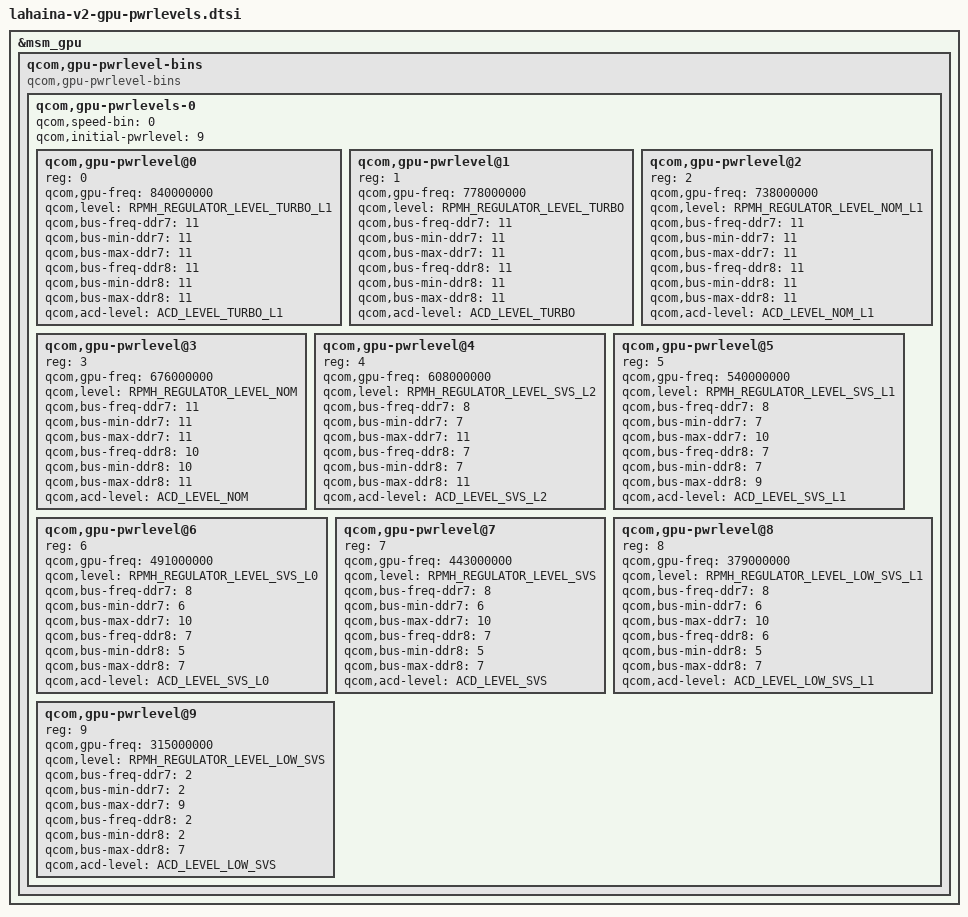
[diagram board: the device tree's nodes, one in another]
// SPDX-License-Identifier: BSD-3-Clause
/*
 * Copyright (c) Qualcomm Technologies, Inc. and/or its subsidiaries.
 */

/* ACD Control register values */
#define ACD_LEVEL_TURBO_L1     0x882a5ffd
#define ACD_LEVEL_TURBO        0xa82a5ffd
#define ACD_LEVEL_NOM_L1       0xa82a5ffd
#define ACD_LEVEL_NOM          0x882b5ffd
#define ACD_LEVEL_SVS_L2       0xa82b5ffd
#define ACD_LEVEL_SVS_L1       0xa82c5ffd
#define ACD_LEVEL_SVS_L0       0xa82c5ffd
#define ACD_LEVEL_SVS          0xa82d5ffd
#define ACD_LEVEL_LOW_SVS_L1   0x882e5ffd
#define ACD_LEVEL_LOW_SVS      0x882f5ffd

&msm_gpu {
	qcom,gpu-pwrlevel-bins {
		#address-cells = <1>;
		#size-cells = <0>;

		compatible = "qcom,gpu-pwrlevel-bins";

		qcom,gpu-pwrlevels-0 {
			#address-cells = <1>;
			#size-cells = <0>;

			qcom,speed-bin = <0>;
			qcom,initial-pwrlevel = <9>;

			/* TURBO_L1 */
			qcom,gpu-pwrlevel@0 {
				reg = <0>;
				qcom,gpu-freq = <840000000>;
				qcom,level = <RPMH_REGULATOR_LEVEL_TURBO_L1>;

				qcom,bus-freq-ddr7 = <11>;
				qcom,bus-min-ddr7 = <11>;
				qcom,bus-max-ddr7 = <11>;

				qcom,bus-freq-ddr8 = <11>;
				qcom,bus-min-ddr8 = <11>;
				qcom,bus-max-ddr8 = <11>;

				qcom,acd-level = <ACD_LEVEL_TURBO_L1>;
			};

			/* TURBO */
			qcom,gpu-pwrlevel@1 {
				reg = <1>;
				qcom,gpu-freq = <778000000>;
				qcom,level = <RPMH_REGULATOR_LEVEL_TURBO>;

				qcom,bus-freq-ddr7 = <11>;
				qcom,bus-min-ddr7 = <11>;
				qcom,bus-max-ddr7 = <11>;

				qcom,bus-freq-ddr8 = <11>;
				qcom,bus-min-ddr8 = <11>;
				qcom,bus-max-ddr8 = <11>;

				qcom,acd-level = <ACD_LEVEL_TURBO>;
			};

			/* NOM_L1 */
			qcom,gpu-pwrlevel@2 {
				reg = <2>;
				qcom,gpu-freq = <738000000>;
				qcom,level = <RPMH_REGULATOR_LEVEL_NOM_L1>;

				qcom,bus-freq-ddr7 = <11>;
				qcom,bus-min-ddr7 = <11>;
				qcom,bus-max-ddr7 = <11>;

				qcom,bus-freq-ddr8 = <11>;
				qcom,bus-min-ddr8 = <11>;
				qcom,bus-max-ddr8 = <11>;

				qcom,acd-level = <ACD_LEVEL_NOM_L1>;
			};

			/* NOM */
			qcom,gpu-pwrlevel@3 {
				reg = <3>;
				qcom,gpu-freq = <676000000>;
				qcom,level = <RPMH_REGULATOR_LEVEL_NOM>;

				qcom,bus-freq-ddr7 = <11>;
				qcom,bus-min-ddr7 = <11>;
				qcom,bus-max-ddr7 = <11>;

				qcom,bus-freq-ddr8 = <10>;
				qcom,bus-min-ddr8 = <10>;
				qcom,bus-max-ddr8 = <11>;

				qcom,acd-level = <ACD_LEVEL_NOM>;
			};

			/* SVS_L2 */
			qcom,gpu-pwrlevel@4 {
				reg = <4>;
				qcom,gpu-freq = <608000000>;
				qcom,level = <RPMH_REGULATOR_LEVEL_SVS_L2>;

				qcom,bus-freq-ddr7 = <8>;
				qcom,bus-min-ddr7 = <7>;
				qcom,bus-max-ddr7 = <11>;

				qcom,bus-freq-ddr8 = <7>;
				qcom,bus-min-ddr8 = <7>;
				qcom,bus-max-ddr8 = <11>;

				qcom,acd-level = <ACD_LEVEL_SVS_L2>;
			};

			/* SVS_L1 */
			qcom,gpu-pwrlevel@5 {
				reg = <5>;
				qcom,gpu-freq = <540000000>;
				qcom,level = <RPMH_REGULATOR_LEVEL_SVS_L1>;

				qcom,bus-freq-ddr7 = <8>;
				qcom,bus-min-ddr7 = <7>;
				qcom,bus-max-ddr7 = <10>;

				qcom,bus-freq-ddr8 = <7>;
				qcom,bus-min-ddr8 = <7>;
				qcom,bus-max-ddr8 = <9>;

				qcom,acd-level = <ACD_LEVEL_SVS_L1>;
			};

			/* SVS_L0 */
			qcom,gpu-pwrlevel@6 {
				reg = <6>;
				qcom,gpu-freq = <491000000>;
				qcom,level = <RPMH_REGULATOR_LEVEL_SVS_L0>;

				qcom,bus-freq-ddr7 = <8>;
				qcom,bus-min-ddr7 = <6>;
				qcom,bus-max-ddr7 = <10>;

				qcom,bus-freq-ddr8 = <7>;
				qcom,bus-min-ddr8 = <5>;
				qcom,bus-max-ddr8 = <7>;

				qcom,acd-level = <ACD_LEVEL_SVS_L0>;
			};

			/* SVS */
			qcom,gpu-pwrlevel@7 {
				reg = <7>;
				qcom,gpu-freq = <443000000>;
				qcom,level = <RPMH_REGULATOR_LEVEL_SVS>;

				qcom,bus-freq-ddr7 = <8>;
				qcom,bus-min-ddr7 = <6>;
				qcom,bus-max-ddr7 = <10>;

				qcom,bus-freq-ddr8 = <7>;
				qcom,bus-min-ddr8 = <5>;
				qcom,bus-max-ddr8 = <7>;

				qcom,acd-level = <ACD_LEVEL_SVS>;
			};

			/* LOW_SVS_L1 */
			qcom,gpu-pwrlevel@8 {
				reg = <8>;
				qcom,gpu-freq = <379000000>;
				qcom,level = <RPMH_REGULATOR_LEVEL_LOW_SVS_L1>;

				qcom,bus-freq-ddr7 = <8>;
				qcom,bus-min-ddr7 = <6>;
				qcom,bus-max-ddr7 = <10>;

				qcom,bus-freq-ddr8 = <6>;
				qcom,bus-min-ddr8 = <5>;
				qcom,bus-max-ddr8 = <7>;

				qcom,acd-level = <ACD_LEVEL_LOW_SVS_L1>;
			};

			/* LOW_SVS */
			qcom,gpu-pwrlevel@9 {
				reg = <9>;
				qcom,gpu-freq = <315000000>;
				qcom,level = <RPMH_REGULATOR_LEVEL_LOW_SVS>;

				qcom,bus-freq-ddr7 = <2>;
				qcom,bus-min-ddr7 = <2>;
				qcom,bus-max-ddr7 = <9>;

				qcom,bus-freq-ddr8 = <2>;
				qcom,bus-min-ddr8 = <2>;
				qcom,bus-max-ddr8 = <7>;

				qcom,acd-level = <ACD_LEVEL_LOW_SVS>;
			};
		};
	};
};
